VERSION ""

NS_ :

BS_:

BU_: IMU_DBC

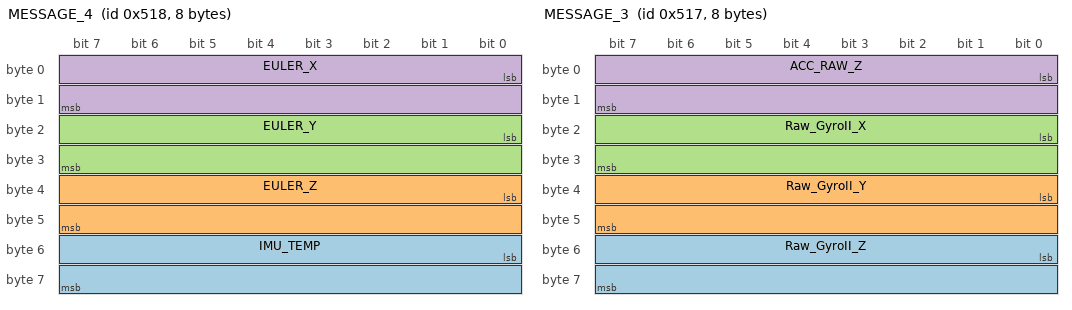
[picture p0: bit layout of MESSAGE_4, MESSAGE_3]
BO_ 1304 MESSAGE_4: 8 Vector__XXX
 SG_ IMU_TEMP : 48|16@1- (0.01,0) [-20|80] "C"  IMU_DBC
 SG_ EULER_Z : 32|16@1- (0.01,0) [-180|180] "deg/s"  IMU_DBC
 SG_ EULER_Y : 16|16@1- (0.01,0) [-90|90] "deg/s"  IMU_DBC
 SG_ EULER_X : 0|16@1- (0.01,0) [-180|180] "deg/s"  IMU_DBC

BO_ 1303 MESSAGE_3: 8 Vector__XXX
 SG_ Raw_GyroII_Z : 48|16@1- (0.1,0) [-1000|1000] "deg/s"  IMU_DBC
 SG_ Raw_GyroII_Y : 32|16@1- (0.1,0) [-1000|1000] "deg/s"  IMU_DBC
 SG_ Raw_GyroII_X : 16|16@1- (0.1,0) [-1000|1000] "deg/s"  IMU_DBC
 SG_ ACC_RAW_Z : 0|16@1- (0.001,0) [-4|4] "g"  IMU_DBC

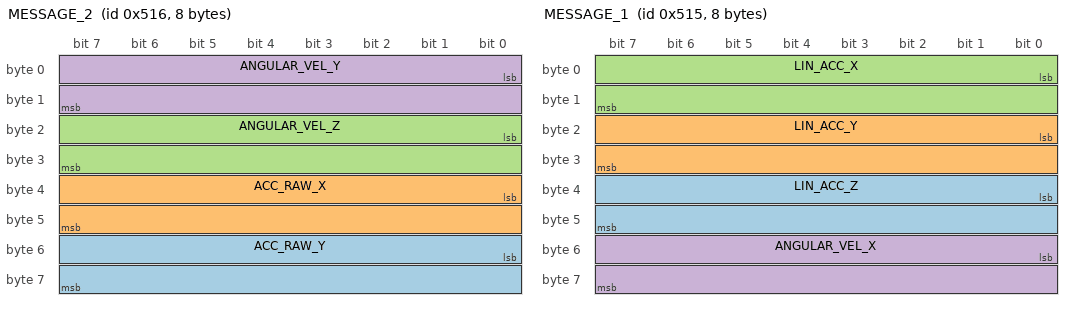
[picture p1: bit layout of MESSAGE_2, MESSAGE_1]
BO_ 1302 MESSAGE_2: 8 Vector__XXX
 SG_ ACC_RAW_Y : 48|16@1- (0.001,0) [-4|4] "g"  IMU_DBC
 SG_ ACC_RAW_X : 32|16@1- (0.001,0) [-4|4] "g"  IMU_DBC
 SG_ ANGULAR_VEL_Z : 16|16@1- (0.01,0) [-125|125] "deg/s"  IMU_DBC
 SG_ ANGULAR_VEL_Y : 0|16@1- (0.01,0) [-327.68|327.67] "deg/s"  IMU_DBC

BO_ 1301 MESSAGE_1: 8 Vector__XXX
 SG_ LIN_ACC_Z : 32|16@1- (0.001,0) [-4|4] "g"  IMU_DBC
 SG_ LIN_ACC_Y : 16|16@1- (0.001,0) [-4|4] "g"  IMU_DBC
 SG_ LIN_ACC_X : 0|16@1- (0.001,0) [-4|4] "g"  IMU_DBC
 SG_ ANGULAR_VEL_X : 48|16@1- (0.01,0) [-125|125] "deg/s"  IMU_DBC

BA_DEF_  "BusType" STRING ;
BA_DEF_DEF_  "BusType" "CAN";
